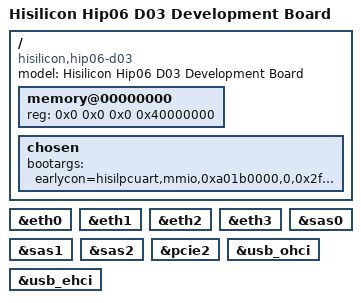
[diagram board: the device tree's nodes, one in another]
/**
 * dts file for Hisilicon D03 Development Board
 *
 * Copyright (C) 2014,2016 Hisilicon Ltd.
 *
 * This program is free software; you can redistribute it and/or modify
 * it under the terms of the GNU General Public License version 2 as
 * publishhed by the Free Software Foundation.
 *
 */

/dts-v1/;

#include "hip06.dtsi"
#include "hip06_hns.dtsi"
/ {
	model = "Hisilicon Hip06 D03 Development Board";
	compatible = "hisilicon,hip06-d03";

	memory@00000000 {
		device_type = "memory";
		reg = <0x0 0x0 0x0 0x40000000>;
	};

	chosen {
		bootargs = "earlycon=hisilpcuart,mmio,0xa01b0000,0,0x2f8 initrd=0x7000000,500M";
	};
};

&eth0 {
	status = "ok";
};

&eth1 {
	status = "ok";
};

&eth2 {
	status = "ok";
};

&eth3 {
	status = "ok";
};

&sas0 {
	status = "okay";
};

&sas1 {
	status = "okay";
};

&sas2 {
	status = "okay";
};

&pcie2 {
	status = "okay";
};

&usb_ohci {
	status = "okay";
};

&usb_ehci {
	status = "okay";
};
